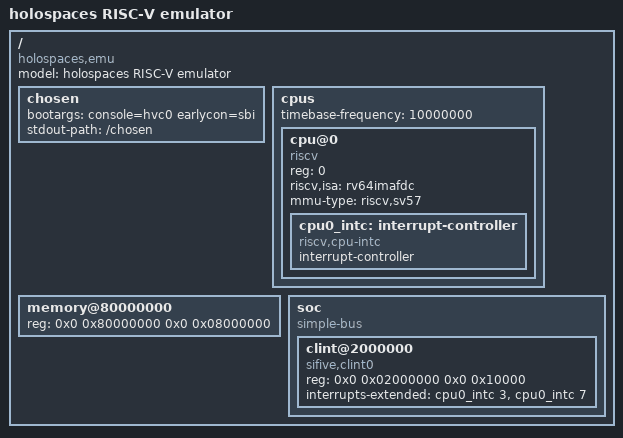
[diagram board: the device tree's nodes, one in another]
/dts-v1/;

/ {
    #address-cells = <2>;
    #size-cells = <2>;
    compatible = "holospaces,emu";
    model = "holospaces RISC-V emulator";

    chosen {
        bootargs = "console=hvc0 earlycon=sbi";
        stdout-path = "/chosen";
    };

    cpus {
        #address-cells = <1>;
        #size-cells = <0>;
        timebase-frequency = <10000000>;

        cpu@0 {
            device_type = "cpu";
            reg = <0>;
            status = "okay";
            compatible = "riscv";
            riscv,isa = "rv64imafdc";
            mmu-type = "riscv,sv57";

            cpu0_intc: interrupt-controller {
                #interrupt-cells = <1>;
                interrupt-controller;
                compatible = "riscv,cpu-intc";
            };
        };
    };

    memory@80000000 {
        device_type = "memory";
        reg = <0x0 0x80000000 0x0 0x08000000>; /* 128 MiB */
    };

    soc {
        #address-cells = <2>;
        #size-cells = <2>;
        compatible = "simple-bus";
        ranges;

        clint@2000000 {
            compatible = "sifive,clint0", "riscv,clint0";
            reg = <0x0 0x02000000 0x0 0x10000>;
            interrupts-extended = <&cpu0_intc 3 &cpu0_intc 7>;
        };
    };
};
